# PIC32MK0128MCA028 device description
Architecture: MIPS; Family: PIC32MK; Series: PIC32MK
Registers are 32-bit, read-write, no defined reset value unless marked. A register's access mark holds for its fields unless they carry their own. Offsets are from the block's base; [hi:lo] are bit positions; {n}, {i} and the like mark numbered series; 'fields as' and 'values as' point back to an identical list.

## RPIN
Instances: RPIN 0x1f801404 in periph_pb1_std
0x00 INT1R
  [3:0] INT1R
0x04 INT2R
  [3:0] INT2R
0x08 INT3R
  [3:0] INT3R
0x0C INT4R
  [3:0] INT4R
{0xC+4i} T{i}CKR (i=2..5)
  [3:0] T{i}CKR
{0x30+4i} IC{i}R (i=1..4)
  [3:0] IC{i}R
0x58 OCFAR
  [3:0] OCFAR
0x5C OCFBR
  [3:0] OCFBR
{0x58+8i} U{i}RXR (i=1..6)
  [3:0] U{i}RXR
{0x5C+8i} U{i}CTSR (i=1..6)
  [3:0] U{i}CTSR
{0x88+0xC*i} SDI{i}R (i=1..4)
  [3:0] SDI{i}R
{0x8C+0xC*i} SS{i}R (i=1..4)
  [3:0] SS{i}R
{0x84+0xC*i} SCK{i}R (i=2..4)
  [3:0] SCK{i}R
0xC8 REFIR
  [3:0] REFIR
0xCC QEA1R
  [3:0] QEA1R
0xD0 QEB1R
  [3:0] QEB1R
0xD4 INDX1R
  [3:0] INDX1R
0xD8 HOME1R
  [3:0] HOME1R
0xDC QEA2R
  [3:0] QEA2R
0xE0 QEB2R
  [3:0] QEB2R
0xE4 INDX2R
  [3:0] INDX2R
0xE8 HOME2R
  [3:0] HOME2R
0xEC FLT1R
  [3:0] FLT1R
0xF0 FLT2R
  [3:0] FLT2R
0x170 CLCINAR
  [3:0] CLCINAR
0x174 CLCINBR
  [3:0] CLCINBR
0x178 CLCINCR
  [3:0] CLCINCR
0x17C CLCINDR
  [3:0] CLCINDR

## RPOR
Instances: RPOR 0x1f801600 in periph_pb1_std
{0x0+4i} RPA{i}R (i=0..4)
  [4:0] RPA{i}R
0x1C RPA7R
  [4:0] RPA7R
0x20 RPA8R
  [4:0] RPA8R
0x2C RPA11R
  [4:0] RPA11R
0x30 RPA12R
  [4:0] RPA12R
{0x40+4i} RPB{i}R (i=0..7)
  [4:0] RPB{i}R
{0x40+4i} RPB{i}R (i=9..15)
  [4:0] RPB{i}R
{0x80+4i} RPC{i}R (i=0..2)
  [4:0] RPC{i}R
{0x80+4i} RPC{i}R (i=6..10)
  [4:0] RPC{i}R
0xB0 RPC12R
  [4:0] RPC12R
0xBC RPC15R
  [4:0] RPC15R
0xE0 RPD8R
  [4:0] RPD8R

## RTCC
Instances: RTCC 0x1f8c0000 in periph_pb6_std
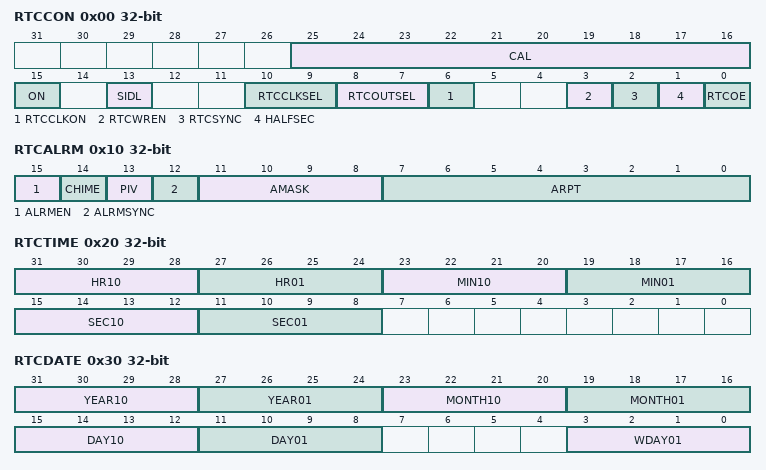
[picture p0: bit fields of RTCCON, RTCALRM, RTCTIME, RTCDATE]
0x00 RTCCON — Real-Time Clock and Calendar Control Register
  [25:16] CAL — Real-Time Clock Drift Calibration bits
    0x1ff=Maximum positive adjustment; 1=Minimum positive adjustment; 0=No adjustment; 0x3ff=Minimum negative adjustment; 0x200=Minimum negative adjustment
  [15] ON — RTCC On bit
    1=RTCC module is enabled; 0=RTCC module is disabled
  [13] SIDL — Stop in Idle Mode bit
    1=Disables RTCC operation when CPU enters Idle mode; 0=Continue normal operation when CPU enters Idle mode
  [10:9] RTCCLKSEL — RTCC Clock Select bits
    1=RTCC uses the external 32.768 kHz Secondary Oscillator (SOSC); 0=RTCC uses the internal 32 kHz oscillator (LPRC)
  [8:7] RTCOUTSEL — RTCC Output Data Select bits
    2=RTCC Clock is presented on the RTCC pin; 1=Seconds Clock is presented on the RTCC pin; 0=Alarm Pulse is presented on the RTCC pin when the alarm interrupt is triggered
  [6] RTCCLKON — RTCC Clock Enable Status bit
    1=RTCC Clock is actively running; 0=RTCC Clock is not running
  [3] RTCWREN — Real-Time Clock Value Registers Write Enable bit
    1=Real-Time Clock Value registers can be written to by the user; 0=Real-Time Clock Value registers are locked out from being written to by the user
  [2] RTCSYNC — Real-Time Clock Value Registers Read Synchronization bit
    1=Real-time clock value registers can change while reading (due to a rollover ripple that results in an invalid data read). If the register is read twice and results in the same data; 0=Real-time clock value registers can be read without concern about a rollover ripple
  [1] HALFSEC — Half-Second Status bit
    1=Second half period of a second; 0=First half period of a second
  [0] RTCOE — RTCC Output Enable bit
    1=RTCC output is enabled; 0=RTCC output is not enabled
0x10 RTCALRM — Real-Time Clock ALARM Control Register
  [15] ALRMEN — Alarm Enable bit
    1=Alarm is enabled; 0=Alarm is disabled
  [14] CHIME — Chime Enable bit
    1=Chime is enabled ARPT is allowed to rollover from 0x00 to 0xFF; 0=Chime is disabled ARPT stops once it reaches 0x00
  [13] PIV — Alarm Pulse Initial Value bit
    0=low initial value of the Alarm Pulse (When ALRMEN = 0); 1=high initial value of the Alarm Pulse (When ALRMEN = 0)
  [12] ALRMSYNC — Alarm Sync bit
    1=ARPT and ALRMEN may change as a result of a half second rollover during a read. The ARPT must be read repeatedly until the same value is read twice. This must be done since multiple bits may be changing.; 0=ARPT and ALRMEN can be read without concerns of rollover because the prescaler is more than 32 real-time clocks away from a half-second rollover
  [11:8] AMASK — Alarm Mask Configuration bits
    0=Every half-second; 1=Every second; 2=Every 10 seconds; 3=Every minute; 4=Every 10 minutes; 5=Every hour; 6=Once a day; 7=Once a week; 8=Once a month; 9=Once a year (except when configured for February 29
  [7:0] ARPT — Alarm Repeat Counter Value bits
    255=Alarm will trigger 256 times; 254=Alarm will trigger 255 times; 1=Alarm will trigger two times; 0=Alarm will trigger one time
0x20 RTCTIME
  [31:28] HR10, [27:24] HR01, [23:20] MIN10, [19:16] MIN01, [15:12] SEC10, [11:8] SEC01
0x30 RTCDATE
  [31:28] YEAR10, [27:24] YEAR01, [23:20] MONTH10, [19:16] MONTH01, [15:12] DAY10, [11:8] DAY01, [3:0] WDAY01
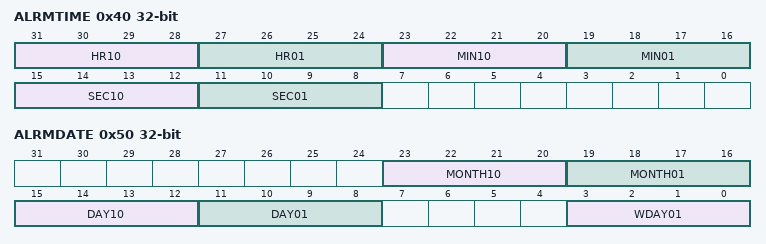
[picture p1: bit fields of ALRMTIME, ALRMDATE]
0x40 ALRMTIME
  fields as RTCTIME
0x50 ALRMDATE
  [23:20] MONTH10, [19:16] MONTH01, [15:12] DAY10, [11:8] DAY01, [3:0] WDAY01

## TMR1
Instances: TMR1 0x1f820000 in periph_pb2_std
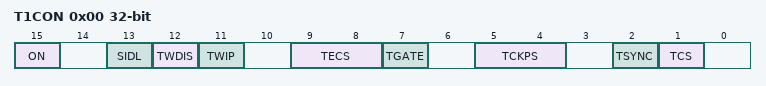
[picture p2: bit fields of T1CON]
0x00 T1CON — TYPE A TIMER CONTROL REGISTER
  [15] ON — Timer On bit
    1=Timer is enabled; 0=Timer is disabled
  [13] SIDL — Stop in Idle Mode bit
    1=Discontinue operation when device enters Idle mode; 0=Continue operation even in Idle mode
  [12] TWDIS — Asynchronous Timer Write Disable bit
    1=Writes to TMR1 are ignored until pending write operation completes; 0=Back-to-back writes are enabled (Legacy Asynchronous Timer functionality)
  [11] TWIP — Asynchronous Timer Write in Progress bit
    1=(In Asynchronous Timer mode) Asynchronous write to TMR1 register in progress / (In Synchronous Timer mode)bit is read as 0; 0=In Asynchronous Timer mode Asynchronous write to TMR1 register complete / (In Synchronous Timer mode)bit is read as 0
  [9:8] TECS — Timer1 External Clock Selection bits
    2=LPRC (External clock comes from the LPRC); 1=T1CK_PIN (External clock comes from the T1CK pin); 0=SOSC (External clock comes from the SOSC)
  [7] TGATE — Timer Gated Time Accumulation Enable bit
    1=(When TCS is 0) Gated time accumulation is enabled / (When TCS is 1) bit is ignored; 0=(When TCS is 0) Gated time accumulation is disabled / (When TCS is 1) bit is ignored
  [5:4] TCKPS — Timer Input Clock Prescale Select bits
    3=1:256 prescale value; 2=1:64 prescale value; 1=1:8 prescale value; 0=1:1 prescale value
  [2] TSYNC — Timer External Clock Input Synchronization Selection bit
    1=(When TCS is 1) External clock input is synchronized / (When TCS is 0) This bit is ignored; 0=(When TCS is 1) External clock input is not synchronized / (When TCS is 0) This bit is ignored
  [1] TCS — Timer Clock Source Select bit
    1=External clock is defined by the TECS bits; 0=Internal peripheral clock
0x10 TMR1
0x20 PR1

## TMR
Instances: TMR 0x1f820200 in periph_pb2_std
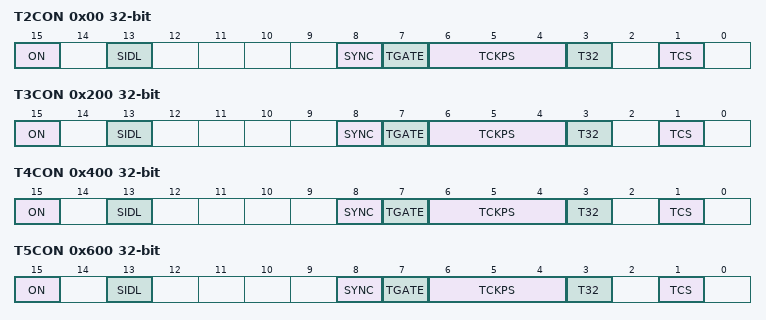
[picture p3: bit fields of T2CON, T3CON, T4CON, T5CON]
0x00 T2CON — Timer Configuration
  [15] ON — Timer On bit
    1=Module is enabled; 0=Module is disabled
  [13] SIDL — Stop in Idle Mode bit
    1=Discontinue operation when device enters Idle mode; 0=Continue operation even in Idle mode
  [8] SYNC — Synchronized Timer Start/Stop Enable bit
    1=Synchronized timer Start/Stop is enabled; 0=Synchronized timer Start/Stop is disabled
  [7] TGATE — Timer Gated Time Accumulation Enable bit
    1=Gated time accumulation is enabled; 0=Gated time accumulation is disabled
  [6:4] TCKPS — Timer Input Clock Prescale Select bits
    7=1:256 prescale value; 6=1:64 prescale value; 5=1:32 prescale value; 4=1:16 prescale value; 3=1:8 prescale value; 2=1:4 prescale value; 1=1:2 prescale value; 0=1:1 prescale value
  [3] T32 — 32-Bit Timer Mode Select bit
    1=32-bit Timer mode; 0=16-bit Timer mode
  [1] TCS — Timer Clock Source Select bit
    1=External clock from TxCK pin; 0=Internal peripheral clock
0x10 TMR2 — Timer
0x20 PR2 — Timer Period
0x200 T3CON — Timer Configuration
  fields as T2CON
0x210 TMR3 — Timer
0x220 PR3 — Timer Period
0x400 T4CON — Timer Configuration
  fields as T2CON
0x410 TMR4 — Timer
0x420 PR4 — Timer Period
0x600 T5CON — Timer Configuration
  fields as T2CON
0x610 TMR5 — Timer
0x620 PR5 — Timer Period

## WDT
Instances: WDT 0x1f800c00 in periph_pb1_std
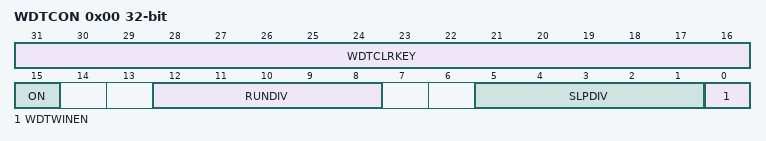
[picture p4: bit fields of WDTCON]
0x00 WDTCON — Watchdog Timer Control Register
  [31:16] WDTCLRKEY — Watchdog Timer Clear Key bits
  [15] ON — Watchdog Timer Enable bit
    1=The WDT module is enabled; 0=The WDT module is disabled
  [12:8] RUNDIV — Watchdog Timer Postscaler Value in Run Mode bits
  [5:1] SLPDIV
  [0] WDTWINEN — Watchdog Timer Window Enable bit
    1=Enable windowed Watchdog Timer; 0=Disable windowed Watchdog Timer
